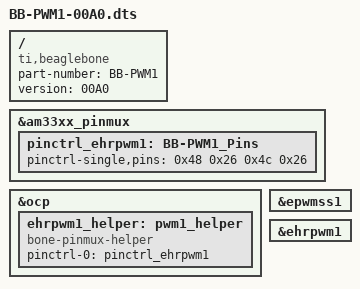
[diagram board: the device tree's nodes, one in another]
/*
 * Copyright (C) 2016 Seeed Studio.
 *
 * This program is free software; you can redistribute it and/or modify
 * it under the terms of the GNU General Public License version 2 as
 * published by the Free Software Foundation.
 */
/dts-v1/;
/plugin/;

/{
    compatible = "ti,beaglebone", "ti,beaglebone-black", "ti,beaglebone-green";
    part-number = "BB-PWM1";
    version = "00A0";

    fragment@0 {
        target = <&am33xx_pinmux>;
            __overlay__ {
            pinctrl_ehrpwm1: BB-PWM1_Pins {
                    pinctrl-single,pins = <
                        0x48 0x26 /* (U14) gpmc_a2.ehrpwm1A */
                        0x4c 0x26 /* (T14) gpmc_a3.ehrpwm1B */
                    >;
                };
            };
    };

fragment@1 {
    target = <&ocp>;
        __overlay__ {
        ehrpwm1_helper: pwm1_helper {
            compatible = "bone-pinmux-helper";
            pinctrl-names = "default";
            pinctrl-0 = <&pinctrl_ehrpwm1>;
            status = "okay";
        };
    };
};

    fragment@2 {
        target = <&epwmss1>;
        __overlay__ {
            status = "okay";
        };
    };

    fragment@3 {
        target = <&ehrpwm1>;
        __overlay__ {
            status = "okay";
        };
    };

};
